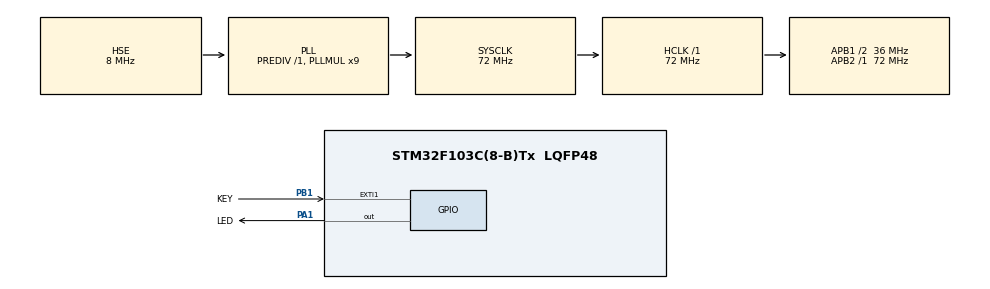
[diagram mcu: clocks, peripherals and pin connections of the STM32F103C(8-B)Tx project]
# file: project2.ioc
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Mcu.Family=STM32F1
Mcu.Name=STM32F103C(8-B)Tx
Mcu.Package=LQFP48
NVIC.EXTI1_IRQn=true\:6\:0\:false\:false\:true\:true\:true\:true
NVIC.PriorityGroup=NVIC_PRIORITYGROUP_4
PA1.GPIO_Label=LED
PA1.Signal=GPIO_Output
PA13.Mode=Serial_Wire
PA13.Signal=SYS_JTMS-SWDIO
PA14.Mode=Serial_Wire
PA14.Signal=SYS_JTCK-SWCLK
PB1.GPIO_PuPd=GPIO_PULLUP
PB1.GPIO_Label=KEY
PB1.GPIO_ModeDefaultEXTI=GPIO_MODE_IT_FALLING
PB1.Signal=GPXTI1
PC14-OSC32_IN.Mode=LSE-External-Oscillator
PC14-OSC32_IN.Signal=RCC_OSC32_IN
PC15-OSC32_OUT.Mode=LSE-External-Oscillator
PC15-OSC32_OUT.Signal=RCC_OSC32_OUT
PD0-OSC_IN.Mode=HSE-External-Oscillator
PD0-OSC_IN.Signal=RCC_OSC_IN
PD1-OSC_OUT.Mode=HSE-External-Oscillator
PD1-OSC_OUT.Signal=RCC_OSC_OUT
ProjectManager.HeapSize=0x200
ProjectManager.StackSize=0x400
ProjectManager.TargetToolchain=MDK-ARM V5.32
RCC.AHBFreq_Value=72000000
RCC.APB1CLKDivider=RCC_HCLK_DIV2
RCC.APB1Freq_Value=36000000
RCC.APB1TimFreq_Value=72000000
RCC.APB2Freq_Value=72000000
RCC.APB2TimFreq_Value=72000000
RCC.HCLKFreq_Value=72000000
RCC.PLLMUL=RCC_PLL_MUL9
RCC.PLLSourceVirtual=RCC_PLLSOURCE_HSE
RCC.SYSCLKFreq_VALUE=72000000
RCC.SYSCLKSource=RCC_SYSCLKSOURCE_PLLCLK
RCC.USBFreq_Value=72000000
board=custom

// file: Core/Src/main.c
/* USER CODE BEGIN Header */
/**
  ******************************************************************************
  * @file           : main.c
  * @brief          : Main program body
  ******************************************************************************
  * @attention
  *
  * Copyright (c) 2026 STMicroelectronics.
  * All rights reserved.
  *
  * This software is licensed under terms that can be found in the LICENSE file
  * in the root directory of this software component.
  * If no LICENSE file comes with this software, it is provided AS-IS.
  *
  ******************************************************************************
  */
/* USER CODE END Header */
#include "main.h"
#include "gpio.h"

/* USER CODE BEGIN PV */
/* 1 = an EXTI edge was seen, the main loop does the real work */
static volatile uint8_t key_flag = 0U;
/* USER CODE END PV */

void SystemClock_Config(void);//
/* USER CODE BEGIN PFP */

/* USER CODE END PFP *//初始化

int main(void)
{

  /* MCU Configuration--------------------------------------------------------*/

  /* Reset of all peripherals, Initializes the Flash interface and the Systick. */
  HAL_Init();

  /* Configure the system clock */
  SystemClock_Config();

  /* Initialize all configured peripherals */
  MX_GPIO_Init();

  /* Infinite loop */
  while (1)
  {

    /* USER CODE BEGIN 3 */

    /* Debounce and LED toggle run here, the interrupt only sets the flag. */
    if (key_flag != 0U)//判断是否按下
    {
      key_flag = 0U;//初始化

      HAL_Delay(20);   //消抖

      if (HAL_GPIO_ReadPin(KEY_GPIO_Port, KEY_Pin) == GPIO_PIN_RESET)//判断是否是低电频
      {
        HAL_GPIO_TogglePin(LED_GPIO_Port, LED_Pin);   //按下取反

        while (HAL_GPIO_ReadPin(KEY_GPIO_Port, KEY_Pin) == GPIO_PIN_RESET)
        {
          HAL_Delay(10);//避免你松手出问题
        }
        HAL_Delay(20);   //消抖
    }
  }
  /* USER CODE END 3 */
}

void SystemClock_Config(void)
{
  RCC_OscInitTypeDef RCC_OscInitStruct = {0};
  RCC_ClkInitTypeDef RCC_ClkInitStruct = {0};

  /** Initializes the RCC Oscillators according to the specified parameters
  * in the RCC_OscInitTypeDef structure.
  */
  RCC_OscInitStruct.OscillatorType = RCC_OSCILLATORTYPE_HSE;
  RCC_OscInitStruct.HSEState = RCC_HSE_ON;
  RCC_OscInitStruct.HSEPredivValue = RCC_HSE_PREDIV_DIV1;
  RCC_OscInitStruct.HSIState = RCC_HSI_ON;
  RCC_OscInitStruct.PLL.PLLState = RCC_PLL_ON;
  RCC_OscInitStruct.PLL.PLLSource = RCC_PLLSOURCE_HSE;
  RCC_OscInitStruct.PLL.PLLMUL = RCC_PLL_MUL9;
  if (HAL_RCC_OscConfig(&RCC_OscInitStruct) != HAL_OK)
  {
    Error_Handler();
  }

  /** Initializes the CPU, AHB and APB buses clocks
  */
  RCC_ClkInitStruct.ClockType = RCC_CLOCKTYPE_HCLK|RCC_CLOCKTYPE_SYSCLK
                              |RCC_CLOCKTYPE_PCLK1|RCC_CLOCKTYPE_PCLK2;
  RCC_ClkInitStruct.SYSCLKSource = RCC_SYSCLKSOURCE_PLLCLK;
  RCC_ClkInitStruct.AHBCLKDivider = RCC_SYSCLK_DIV1;
  RCC_ClkInitStruct.APB1CLKDivider = RCC_HCLK_DIV2;
  RCC_ClkInitStruct.APB2CLKDivider = RCC_HCLK_DIV1;

  if (HAL_RCC_ClockConfig(&RCC_ClkInitStruct, FLASH_LATENCY_2) != HAL_OK)
  {
    Error_Handler();
  }
}

/* USER CODE BEGIN 4 */
/**
  * @brief  EXTI callback for the key on PB1 (EXTI line 1).
  * @note   Only set a flag and return. Do NOT call HAL_Delay() or wait for the
  *         key release in here: SysTick runs at priority 15 (the lowest) and
  *         can not preempt this ISR, so any blocking wait would hang the CPU.
  */
void HAL_GPIO_EXTI_Callback(uint16_t GPIO_Pin)
{
  if (GPIO_Pin == KEY_Pin)   //确认按键就是PB1
  {
    key_flag = 1U;//按下后
  }
}
/* USER CODE END 4 */

void Error_Handler(void)
{
  __disable_irq();
  while (1)
  {
  }
}
